# CH32V203G6U6 register map
Vendor: WCH; File version: 0.1.0
CPU: QingKe V4B V4B, little endian, no MPU, no FPU, vendor SysTick, 4 interrupt priority bits
Registers are 16-bit, read-write, reset 0x0 unless marked. A register's access mark holds for its fields unless they carry their own. Offsets are from the block's base; [hi:lo] are bit positions; {n}, {i} and the like mark numbered series.

## USBD — USB device-only interface
Base 0x50000000
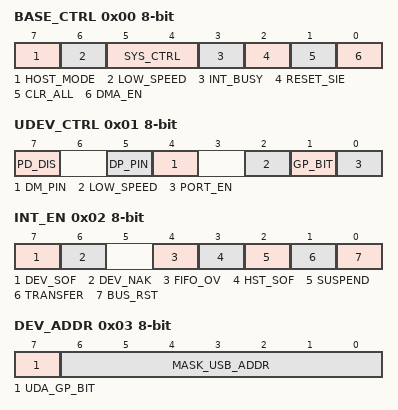
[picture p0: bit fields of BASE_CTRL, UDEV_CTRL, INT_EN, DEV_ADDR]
0x00 BASE_CTRL 8-bit reset not defined — USB base control.
  [7] HOST_MODE — enable USB host mode: 0=device mode, 1=host mode.
  [6] LOW_SPEED — enable USB low speed: 0=12Mbps, 1=1.5Mbps.
  [5:4] SYS_CTRL — USB device enable and internal pullup resistance enable.
  [3] INT_BUSY — enable automatic responding busy for device mode or automatic pause for host mode during interrupt flag UIF_TRANSFER valid.
  [2] RESET_SIE — force reset USB SIE, need software clear.
  [1] CLR_ALL — force clear FIFO and count of USB.
  [0] DMA_EN — DMA enable and DMA interrupt enable for USB.
0x01 UDEV_CTRL 8-bit reset not defined — USB device physical port control register.
  [7] PD_DIS — USB device port UD+/UD- pin internal pull-down resistor control.
  [5] DP_PIN — USB device port UD+ pin status.
  [4] DM_PIN — USB device port UD- pin status.
  [2] LOW_SPEED — USB device port low speed enable.
  [1] GP_BIT — USB device port general purpose bit.
  [0] PORT_EN — USB device port enable.
0x02 INT_EN 8-bit reset not defined — USB interrupt enable.
  [7] DEV_SOF — enable interrupt for SOF received for USB device mode.
  [6] DEV_NAK — enable interrupt for NAK responded for USB device mode.
  [4] FIFO_OV — enable interrupt for FIFO overflow.
  [3] HST_SOF — enable interrupt for host SOF timer action for USB host mode.
  [2] SUSPEND — enable interrupt for USB suspend or resume event.
  [1] TRANSFER — enable interrupt for USB transfer completion.
  [0] BUS_RST — enable interrupt for USB bus reset event for USB device mode.
0x03 DEV_ADDR 8-bit reset not defined — USB device address.
  [7] UDA_GP_BIT — general purpose bit.
  [6:0] MASK_USB_ADDR — bit mask for USB device address.
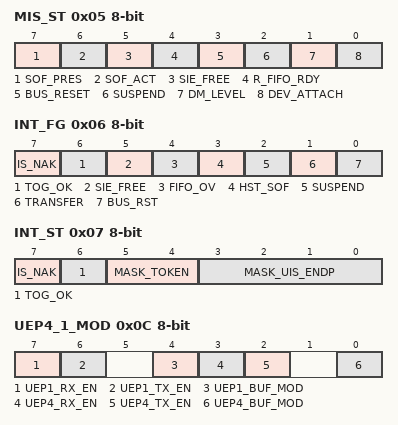
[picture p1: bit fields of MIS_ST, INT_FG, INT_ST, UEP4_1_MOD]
0x05 MIS_ST 8-bit reset not defined — USB miscellaneous status.
  [7] SOF_PRES ro — Indicate host SOF timer presage status.
  [6] SOF_ACT ro — Indicate host SOF timer action status for USB host.
  [5] SIE_FREE ro — Indicate USB SIE free status.
  [4] R_FIFO_RDY ro — Indicate USB receiving FIFO ready status (not empty).
  [3] BUS_RESET ro — Indicate USB bus reset status.
  [2] SUSPEND ro — Indicate USB suspend status.
  [1] DM_LEVEL ro — Indicate UDM level saved at device attached to USB host.
  [0] DEV_ATTACH ro — Indicate device attached status on USB host.
0x06 INT_FG 8-bit reset not defined — USB interrupt flag.
  [7] IS_NAK ro — Indicate current USB transfer is NAK received.
  [6] TOG_OK ro — Indicate current USB transfer toggle is OK.
  [5] SIE_FREE ro — Indicate USB SIE free status.
  [4] FIFO_OV — FIFO overflow interrupt flag for USB, direct bit address clear or write 1 to clear.
  [3] HST_SOF — host SOF timer interrupt flag for USB host, direct bit address clear or write 1 to clear.
  [2] SUSPEND — USB suspend or resume event interrupt flag, direct bit address clear or write 1 to clear.
  [1] TRANSFER — USB transfer completion interrupt flag, direct bit address clear or write 1 to clear.
  [0] BUS_RST — bus reset event interrupt flag for USB device mode, direct bit address clear or write 1 to clear
0x07 INT_ST 8-bit reset not defined — USB interrupt status.
  [7] IS_NAK ro — Indicate current USB transfer is NAK received for USB device mode.
  [6] TOG_OK ro — Indicate current USB transfer toggle is OK.
  [5:4] MASK_TOKEN ro — Bit mask of current token PID code received for USB device mode.
    0=OUT (OUT Packet); 2=IN (IN Packet); 3=SETUP (Setup Packet)
  [3:0] MASK_UIS_ENDP ro — Bit mask of current transfer endpoint number for USB device mode.
0x08 RX_LEN 32-bit reset not defined — USB receiving length.
  [9:0] RX_LEN — receiving length.
0x0C UEP4_1_MOD 8-bit reset not defined — endpoint 4/1 mode.
  [7] UEP1_RX_EN — enable USB endpoint 1 receiving (OUT).
  [6] UEP1_TX_EN — enable USB endpoint 1 transmittal (IN).
  [4] UEP1_BUF_MOD — buffer mode of USB endpoint 1.
    0=SINGLE (Single Buffer Mode); 1=DOUBLE (Double Buffer Mode)
  [3] UEP4_RX_EN — enable USB endpoint 4 receiving (OUT).
  [2] UEP4_TX_EN — enable USB endpoint 4 transmittal (IN).
  [0] UEP4_BUF_MOD — buffer mode of USB endpoint 4.
    0=SINGLE (Single Buffer Mode); 1=DOUBLE (Double Buffer Mode)
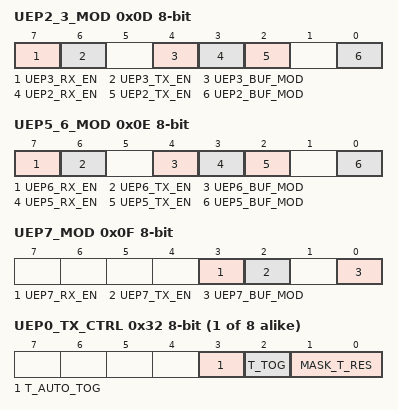
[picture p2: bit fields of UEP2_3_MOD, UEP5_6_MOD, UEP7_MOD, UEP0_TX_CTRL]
0x0D UEP2_3_MOD 8-bit reset not defined — Endpoint 2/3 mode control register.
  [7] UEP3_RX_EN — enable USB endpoint 3 receiving (OUT).
  [6] UEP3_TX_EN — enable USB endpoint 3 transmittal (IN).
  [4] UEP3_BUF_MOD — buffer mode of USB endpoint 3.
    0=SINGLE (Single Buffer Mode); 1=DOUBLE (Double Buffer Mode)
  [3] UEP2_RX_EN — enable USB endpoint 2 receiving (OUT).
  [2] UEP2_TX_EN — enable USB endpoint 2 transmittal (IN).
  [0] UEP2_BUF_MOD — buffer mode of USB endpoint 2.
    0=SINGLE (Single Buffer Mode); 1=DOUBLE (Double Buffer Mode)
0x0E UEP5_6_MOD 8-bit reset not defined — endpoint 5/6 mode.
  [7] UEP6_RX_EN — enable USB endpoint 6 receiving (OUT).
  [6] UEP6_TX_EN — enable USB endpoint 6 transmittal (IN).
  [4] UEP6_BUF_MOD — buffer mode of USB endpoint 6.
    0=SINGLE (Single Buffer Mode); 1=DOUBLE (Double Buffer Mode)
  [3] UEP5_RX_EN — enable USB endpoint 5 receiving (OUT).
  [2] UEP5_TX_EN — enable USB endpoint 5 transmittal (IN).
  [0] UEP5_BUF_MOD — buffer mode of USB endpoint 5.
    0=SINGLE (Single Buffer Mode); 1=DOUBLE (Double Buffer Mode)
0x0F UEP7_MOD 8-bit reset not defined — endpoint 7 mode.
  [3] UEP7_RX_EN — enable USB endpoint 7 receiving (OUT).
  [2] UEP7_TX_EN — enable USB endpoint 7 transmittal (IN).
  [0] UEP7_BUF_MOD — buffer mode of USB endpoint 7.
    0=SINGLE (Single Buffer Mode); 1=DOUBLE (Double Buffer Mode)
{0x10+4i} UEP{i}_DMA 32-bit reset not defined (i=0..7) — endpoint DMA buffer address.
{0x30+4i} UEP{i}_TX_LEN reset not defined (i=0..7) — endpoint transmit length.
{0x32+4i} UEP{i}_TX_CTRL 8-bit reset not defined (i=0..7) — endpoint control.
  [3] T_AUTO_TOG — enable automatic toggle after successful transfer completion on endpoint 1/2/3: 0=manual toggle, 1=automatic toggle.
  [2] T_TOG — prepared data toggle flag of USB endpoint X transmittal (IN): 0=DATA0, 1=DATA1.
  [1:0] MASK_T_RES — bit mask of handshake response type for USB endpoint X transmittal (IN).
    0=ACK (Respond with DATA0/DATA1 and expect ACK); 1=None (Respond with DATA0/DATA1 and not expect ACK); 2=NAK (Respond with NAK or Busy); 3=STALL (Respond with STALL or Error)
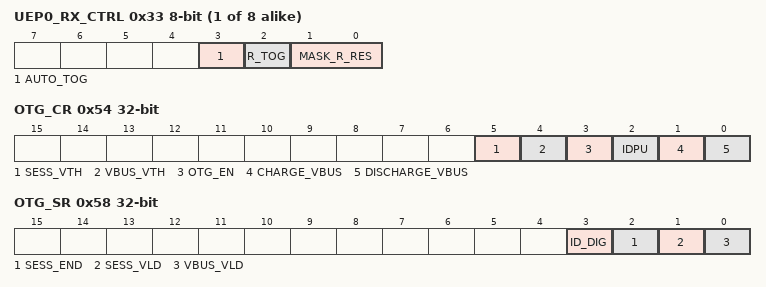
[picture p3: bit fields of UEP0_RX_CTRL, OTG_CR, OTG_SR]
{0x33+4i} UEP{i}_RX_CTRL 8-bit reset not defined (i=0..7) — endpoint control.
  [3] AUTO_TOG — enable automatic toggle after successful transfer completion on endpoint 1/2/3: 0=manual toggle, 1=automatic toggle.
  [2] R_TOG — expected data toggle flag of USB endpoint X receiving (OUT): 0=DATA0, 1=DATA1.
  [1:0] MASK_R_RES — bit mask of handshake response type for USB endpoint X receiving (OUT).
    0=ACK (Respond with ACK); 1=None (Timeout / No Response, used for non-EP0 iso/sync transfer); 2=NAK (Respond with NAK or Busy); 3=STALL (Respond with STALL or Error)
0x54 OTG_CR 32-bit reset not defined — usb otg control.
  [5] SESS_VTH — usb otg control.
  [4] VBUS_VTH — usb otg control.
  [3] OTG_EN — usb otg control.
  [2] IDPU — usb otg control.
  [1] CHARGE_VBUS — usb otg control.
  [0] DISCHARGE_VBUS — usb otg control.
0x58 OTG_SR 32-bit reset not defined — usb otg status.
  [3] ID_DIG — usb otg status.
  [2] SESS_END — usb otg status.
  [1] SESS_VLD — usb otg status.
  [0] VBUS_VLD — usb otg status.
